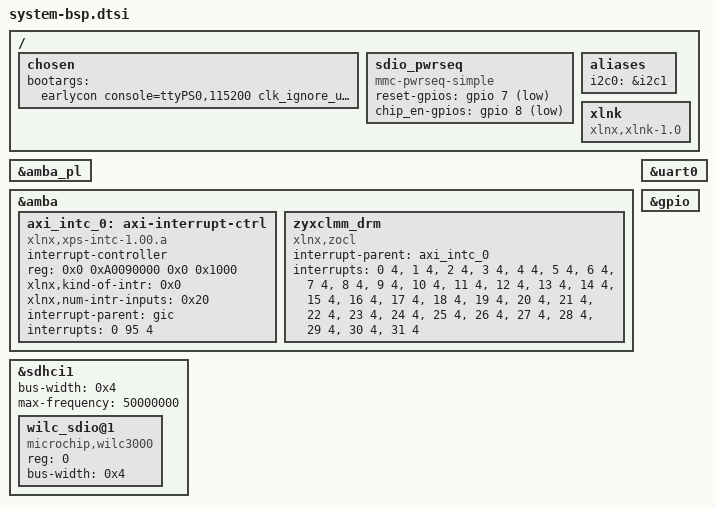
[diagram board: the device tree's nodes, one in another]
/include/ "system-conf.dtsi"
/include/ "openamp.dtsi"
/ {
	chosen {
		bootargs = "earlycon console=ttyPS0,115200 clk_ignore_unused root=/dev/mmcblk0p2 rw rootwait cma=512M";
	};

   sdio_pwrseq: sdio_pwrseq {  /* This needs to be able to manipulate the chip_en and the resetn properly */
      compatible = "mmc-pwrseq-simple";
      /* post-power-on-delay-ms = <10>; */
      reset-gpios = <&gpio 7 1>; // MIO[7] for WILC3000 RESETN, Active low
      /* reset-gpios = <&gpio 78 1>;  // Some prototype boards only! device pin A3 for RESETN, Active low */
      chip_en-gpios = <&gpio 8 1>; 
   };

   // Remove V1 Power ON/OFF controller from U96 V1 DT
   /delete-node/ ltc2954;

	aliases {
		i2c0 = &i2c1;
   };
   
   xlnk {
      compatible = "xlnx,xlnk-1.0";
   };

};

&amba_pl {
   // Remove definitions auto-generated by device tree generator
   /delete-node/interrupt-controller@a0090000; // axi_intc_0
};

&amba {
	axi_intc_0: axi-interrupt-ctrl {
		#interrupt-cells = <2>;
		compatible = "xlnx,xps-intc-1.00.a";
		interrupt-controller;
		reg = <0x0 0xA0090000 0x0 0x1000>;
		xlnx,kind-of-intr = <0x0>;
		xlnx,num-intr-inputs = <0x20>;
		interrupt-parent = <&gic>;
		// connected at PS interrupt offset [6] (89+6=95) 
		interrupts = <0 95 4>;
	};

	zyxclmm_drm {
		compatible = "xlnx,zocl";
		status = "okay";
		interrupt-parent = <&axi_intc_0>;
		interrupts = <0  4>, <1  4>, <2  4>, <3  4>,
			     <4  4>, <5  4>, <6  4>, <7  4>,
			     <8  4>, <9  4>, <10 4>, <11 4>,
			     <12 4>, <13 4>, <14 4>, <15 4>,
			     <16 4>, <17 4>, <18 4>, <19 4>,
			     <20 4>, <21 4>, <22 4>, <23 4>,
			     <24 4>, <25 4>, <26 4>, <27 4>,
			     <28 4>, <29 4>, <30 4>, <31 4>;
	};
};

&uart0 {
   // Remove TI child node from U96 V1 DT
   /delete-node/bluetooth;
};

&gpio {
   /delete-property/gpio-line-names;
};

&sdhci1 {
   bus-width= <0x4>;
   /* non-removeable; */
   /* mmc-pwrseq = <&sdio_pwrseq>; */
   max-frequency = <50000000>;
   /delete-property/cap-power-off-card; // This is not compatible with the WILC3000 and means the WILC will always be powered on
   status = "okay";
   #address-cells = <1>;
   #size-cells = <0>;
   wilc_sdio@1 {
      compatible = "microchip,wilc3000", "microchip,wilc3000";
      reg = <0>;
      // interrupt-parent = <&gpio>; // Microchip driver DOES NOT use gpio irq any more!
      // interrupts = <76 2>; /* MIO76 WILC IRQ 1V8 */ // Microchip driver DOES NOT use gpio irq any more!
      // irq-gpios = <&gpio 76 0>; // Microchip driver DOES NOT use gpio irq any more!
      bus-width= <0x4>;
      status = "okay";
   };
   // Remove TI child node from U96 V1 DT
   /delete-node/wifi@2;
};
